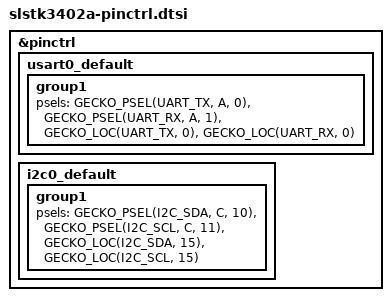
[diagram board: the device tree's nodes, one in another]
/*
 * Copyright (c) 2023 Silicon Labs
 *
 * SPDX-License-Identifier: Apache-2.0
 */

#include <dt-bindings/pinctrl/gecko-pinctrl-s1.h>

&pinctrl {
	/* configuration for usart0 device, default state - operating as UART */
	usart0_default: usart0_default {
		group1 {
			psels = <GECKO_PSEL(UART_TX, A, 0)>,
				<GECKO_PSEL(UART_RX, A, 1)>,
				<GECKO_LOC(UART_TX, 0)>,
				<GECKO_LOC(UART_RX, 0)>;
		};
	};

	i2c0_default: i2c0_default {
		group1 {
			psels = <GECKO_PSEL(I2C_SDA, C, 10)>,
				<GECKO_PSEL(I2C_SCL, C, 11)>,
				<GECKO_LOC(I2C_SDA, 15)>,
				<GECKO_LOC(I2C_SCL, 15)>;
		};
	};
};
